# STM32H743x register map
File version: 1.0
CPU: CM7 r0p1, little endian, MPU, FPU, 4 interrupt priority bits
Registers are 32-bit, read-write, reset 0x0 unless marked. A register's access mark holds for its fields unless they carry their own. Offsets are from the block's base; [hi:lo] are bit positions.

## SPI1 — Serial peripheral interface
Base 0x40013000
Same registers: SPI2 0x40003800, SPI3 0x40003C00, SPI4 0x40013400, SPI5 0x40015000, SPI6 0x58001400
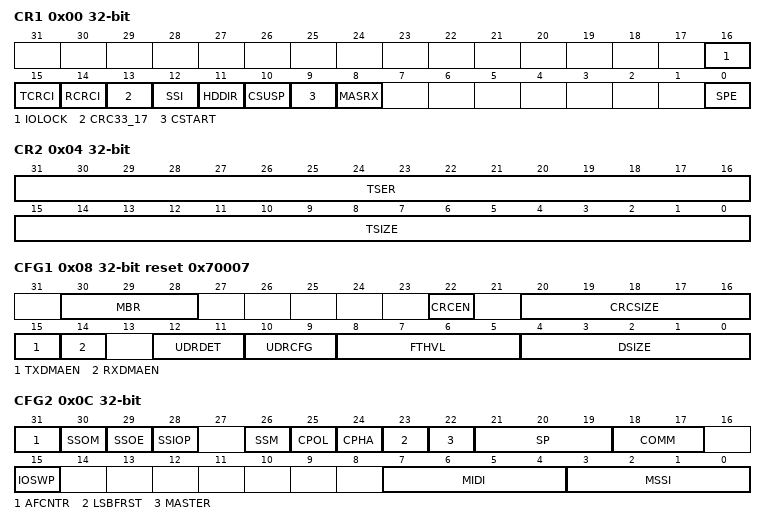
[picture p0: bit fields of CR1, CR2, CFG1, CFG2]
0x00 CR1 access per field — control register 1
  [16] IOLOCK ro — Locking the AF configuration of associated IOs
  [15] TCRCI rw — CRC calculation initialization pattern control for transmitter
  [14] RCRCI rw — CRC calculation initialization pattern control for receiver
  [13] CRC33_17 rw — 32-bit CRC polynomial configuration
  [12] SSI rw — Internal SS signal input level
  [11] HDDIR rw — Rx/Tx direction at Half-duplex mode
  [10] CSUSP wo — Master SUSPend request
  [9] CSTART ro — Master transfer start
  [8] MASRX rw — Master automatic SUSP in Receive mode
  [0] SPE rw — Serial Peripheral Enable
0x04 CR2 access per field — control register 2
  [31:16] TSER ro — Number of data transfer extension to be reload into TSIZE just when a previous
  [15:0] TSIZE rw — Number of data at current transfer
0x08 CFG1 reset 0x70007 — configuration register 1
  [30:28] MBR — Master baud rate
  [22] CRCEN — Hardware CRC computation enable
  [20:16] CRCSIZE — Length of CRC frame to be transacted and compared
  [15] TXDMAEN — Tx DMA stream enable
  [14] RXDMAEN — Rx DMA stream enable
  [12:11] UDRDET — Detection of underrun condition at slave transmitter
  [10:9] UDRCFG — Behavior of slave transmitter at underrun condition
  [8:5] FTHVL — threshold level
  [4:0] DSIZE — Number of bits in at single SPI data frame
0x0C CFG2 — configuration register 2
  [31] AFCNTR — Alternate function GPIOs control
  [30] SSOM — SS output management in master mode
  [29] SSOE — SS output enable
  [28] SSIOP — SS input/output polarity
  [26] SSM — Software management of SS signal input
  [25] CPOL — Clock polarity
  [24] CPHA — Clock phase
  [23] LSBFRST — Data frame format
  [22] MASTER — SPI Master
  [21:19] SP — Serial Protocol
  [18:17] COMM — SPI Communication Mode
  [15] IOSWP — Swap functionality of MISO and MOSI pins
  [7:4] MIDI — Master Inter-Data Idleness
  [3:0] MSSI — Master SS Idleness
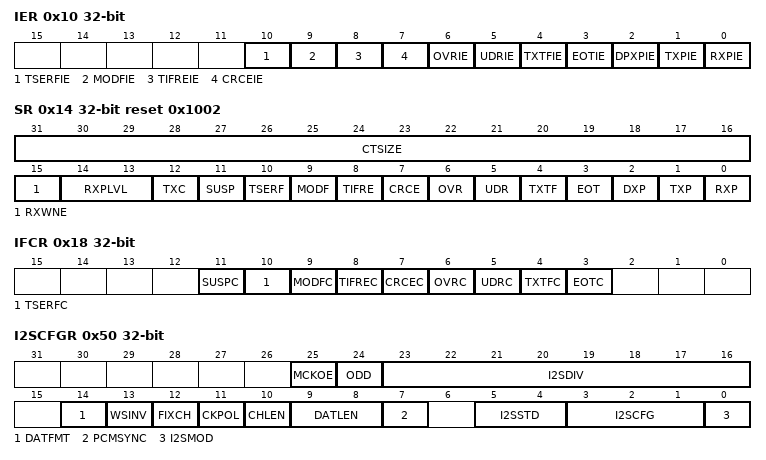
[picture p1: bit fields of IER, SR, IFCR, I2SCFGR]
0x10 IER access per field — Interrupt Enable Register
  [10] TSERFIE rw — Additional number of transactions reload interrupt enable
  [9] MODFIE rw — Mode Fault interrupt enable
  [8] TIFREIE rw — TIFRE interrupt enable
  [7] CRCEIE rw — CRC Interrupt enable
  [6] OVRIE rw — OVR interrupt enable
  [5] UDRIE rw — UDR interrupt enable
  [4] TXTFIE rw — TXTFIE interrupt enable
  [3] EOTIE rw — EOT, SUSP and TXC interrupt enable
  [2] DPXPIE ro — DXP interrupt enabled
  [1] TXPIE ro — TXP interrupt enable
  [0] RXPIE rw — RXP Interrupt Enable
0x14 SR ro reset 0x1002 — Status Register
  [31:16] CTSIZE — Number of data frames remaining in current TSIZE session
  [15] RXWNE — RxFIFO Word Not Empty
  [14:13] RXPLVL — RxFIFO Packing LeVeL
  [12] TXC — TxFIFO transmission complete
  [11] SUSP — SUSPend
  [10] TSERF — Additional number of SPI data to be transacted was reload
  [9] MODF — Mode Fault
  [8] TIFRE — TI frame format error
  [7] CRCE — CRC Error
  [6] OVR — Overrun
  [5] UDR — Underrun at slave transmission mode
  [4] TXTF — Transmission Transfer Filled
  [3] EOT — End Of Transfer
  [2] DXP — Duplex Packet
  [1] TXP — Tx-Packet space available
  [0] RXP — Rx-Packet available
0x18 IFCR wo — Interrupt/Status Flags Clear Register
  [11] SUSPC — SUSPend flag clear
  [10] TSERFC — TSERFC flag clear
  [9] MODFC — Mode Fault flag clear
  [8] TIFREC — TI frame format error flag clear
  [7] CRCEC — CRC Error flag clear
  [6] OVRC — Overrun flag clear
  [5] UDRC — Underrun flag clear
  [4] TXTFC — Transmission Transfer Filled flag clear
  [3] EOTC — End Of Transfer flag clear
0x20 TXDR wo — Transmit Data Register
  [31:0] TXDR — Transmit data register
0x30 RXDR ro — Receive Data Register
  [31:0] RXDR — Receive data register
0x40 CRCPOLY reset 0x107 — Polynomial Register
  [31:0] CRCPOLY — CRC polynomial register
0x44 TXCRC — Transmitter CRC Register
  [31:0] TXCRC — CRC register for transmitter
0x48 RXCRC — Receiver CRC Register
  [31:0] RXCRC — CRC register for receiver
0x4C UDRDR — Underrun Data Register
  [31:0] UDRDR — Data at slave underrun condition
0x50 I2SCFGR — SPI/I2S configuration register
  [25] MCKOE — Master clock output enable
  [24] ODD — Odd factor for the prescaler
  [23:16] I2SDIV — I2S linear prescaler
  [14] DATFMT — Data format
  [13] WSINV — Fixed channel length in SLAVE
  [12] FIXCH — Word select inversion
  [11] CKPOL — Serial audio clock polarity
  [10] CHLEN — Channel length (number of bits per audio channel)
  [9:8] DATLEN — Data length to be transferred
  [7] PCMSYNC — PCM frame synchronization
  [5:4] I2SSTD — I2S standard selection
  [3:1] I2SCFG — I2S configuration mode
  [0] I2SMOD — I2S mode selection
